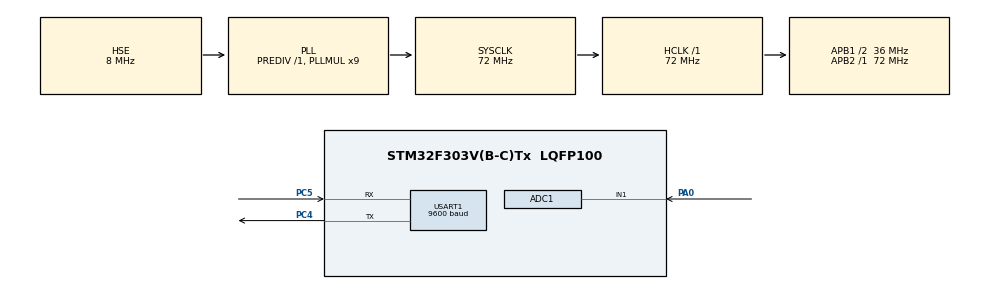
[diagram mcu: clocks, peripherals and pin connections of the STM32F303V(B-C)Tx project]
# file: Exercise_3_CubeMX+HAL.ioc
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ADC1.Channel-0\#ChannelRegularConversion=ADC_CHANNEL_1
ADC1.ContinuousConvMode=ENABLE
ADC1.NbrOfConversion=1
ADC1.NbrOfConversionFlag=1
ADC1.Offset-0\#ChannelRegularConversion=0
ADC1.OffsetNumber-0\#ChannelRegularConversion=ADC_OFFSET_NONE
ADC1.Rank-0\#ChannelRegularConversion=1
ADC1.Resolution=ADC_RESOLUTION_12B
ADC1.SamplingTime-0\#ChannelRegularConversion=ADC_SAMPLETIME_1CYCLE_5
ADC1.master=1
Dma.ADC1.0.Direction=DMA_PERIPH_TO_MEMORY
Dma.ADC1.0.Instance=DMA1_Channel1
Dma.ADC1.0.MemDataAlignment=DMA_MDATAALIGN_WORD
Dma.ADC1.0.MemInc=DMA_MINC_ENABLE
Dma.ADC1.0.Mode=DMA_NORMAL
Dma.ADC1.0.PeriphDataAlignment=DMA_PDATAALIGN_HALFWORD
Dma.ADC1.0.PeriphInc=DMA_PINC_DISABLE
Dma.ADC1.0.Priority=DMA_PRIORITY_LOW
Dma.Request0=ADC1
Dma.Request1=USART1_TX
Dma.USART1_TX.1.Direction=DMA_MEMORY_TO_PERIPH
Dma.USART1_TX.1.Instance=DMA1_Channel4
Dma.USART1_TX.1.MemDataAlignment=DMA_MDATAALIGN_BYTE
Dma.USART1_TX.1.MemInc=DMA_MINC_ENABLE
Dma.USART1_TX.1.Mode=DMA_NORMAL
Dma.USART1_TX.1.PeriphDataAlignment=DMA_PDATAALIGN_BYTE
Dma.USART1_TX.1.PeriphInc=DMA_PINC_DISABLE
Dma.USART1_TX.1.Priority=DMA_PRIORITY_LOW
Mcu.Family=STM32F3
Mcu.Name=STM32F303V(B-C)Tx
Mcu.Package=LQFP100
NVIC.DMA1_Channel1_IRQn=true\:0\:0\:false\:false\:true\:false\:true
NVIC.DMA1_Channel4_IRQn=true\:0\:0\:false\:false\:true\:false\:true
NVIC.PriorityGroup=NVIC_PRIORITYGROUP_4
PA0.Mode=IN1-Single-Ended
PA0.Signal=ADC1_IN1
PA13.Mode=Serial_Wire
PA13.Signal=SYS_JTMS-SWDIO
PA14.Mode=Serial_Wire
PA14.Signal=SYS_JTCK-SWCLK
PC4.Mode=Asynchronous
PC4.Signal=USART1_TX
PC5.Mode=Asynchronous
PC5.Signal=USART1_RX
PF0-OSC_IN.Mode=HSE-External-Clock-Source
PF0-OSC_IN.Signal=RCC_OSC_IN
ProjectManager.HeapSize=0x200
ProjectManager.StackSize=0x400
ProjectManager.TargetToolchain=MDK-ARM V5
RCC.ADC12PRES=RCC_ADC12PLLCLK_DIV2
RCC.AHBFreq_Value=72000000
RCC.APB1CLKDivider=RCC_HCLK_DIV2
RCC.APB1Freq_Value=36000000
RCC.APB1TimFreq_Value=72000000
RCC.APB2Freq_Value=72000000
RCC.APB2TimFreq_Value=72000000
RCC.CortexFreq_Value=72000000
RCC.HCLKFreq_Value=72000000
RCC.HSE_VALUE=8000000
RCC.HSI_VALUE=8000000
RCC.LSE_VALUE=32768
RCC.PLLMUL=RCC_PLL_MUL9
RCC.PLLSourceVirtual=RCC_PLLSOURCE_HSE
RCC.SYSCLKFreq_VALUE=72000000
RCC.SYSCLKSourceVirtual=RCC_SYSCLKSOURCE_PLLCLK
RCC.USBFreq_Value=72000000
USART1.BaudRate=9600
USART1.VirtualMode-Asynchronous=VM_ASYNC
board=custom

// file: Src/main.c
/* USER CODE BEGIN Header */
/**
  ******************************************************************************
  * @file           : main.c
  * @brief          : Main program body
  ******************************************************************************
  * @attention
  *
  * <h2><center>&copy; Copyright (c) 2019 STMicroelectronics.
  * All rights reserved.</center></h2>
  *
  * This software component is licensed by ST under BSD 3-Clause license,
  * the "License"; You may not use this file except in compliance with the
  * License. You may obtain a copy of the License at:
  *                        opensource.org/licenses/BSD-3-Clause
  *
  ******************************************************************************
  */
/* USER CODE END Header */

#include "main.h"
#include "adc.h"
#include "dma.h"
#include "usart.h"
#include "gpio.h"

/* USER CODE BEGIN Includes */
	#include <string.h>
	#include <stdio.h>

	#include <../Lib/arr.h>
/* USER CODE END Includes */

/* USER CODE BEGIN PD */

	#define ADC_SAMPLES 5

/* USER CODE END PD */

/* USER CODE BEGIN PV */

	/// store current ADC 8-bit values
	uint32_t adc_curr[ADC_SAMPLES];
	uint32_t adc_prev[ADC_SAMPLES];

	/// store ADC conversion compleate flag
	uint8_t adc_cplt_f = 0;

/* USER CODE END PV */

void SystemClock_Config(void);
/* USER CODE BEGIN PFP */

/** \brief	Set conversion compleat flag (redefined callback).
 *
 * \param[in] hadc	Pointer to ADC control struct.
 */
void HAL_ADC_ConvCpltCallback(ADC_HandleTypeDef* hadc)
{
	adc_cplt_f = 1;		// set conversion completed flag
}

/* USER CODE END PFP */

int main(void)
{

  /* MCU Configuration--------------------------------------------------------*/

  /* Reset of all peripherals, Initializes the Flash interface and the Systick. */
  HAL_Init();

  /* Configure the system clock */
  SystemClock_Config();

  /* Initialize all configured peripherals */
  MX_GPIO_Init();
  MX_DMA_Init();
  MX_ADC1_Init();
  MX_USART1_UART_Init();
  /* USER CODE BEGIN 2 */

	uint8_t welcome_msg[] = {"\n\r12bit ADC1 ch1 - PA0 (Blue button) values:\n\r"};
	HAL_UART_Transmit(&huart1, welcome_msg, strlen((char*)welcome_msg), 1000);

  /* USER CODE END 2 */

  /* Infinite loop */
  /* USER CODE BEGIN WHILE */

	HAL_ADC_Start_DMA(&hadc1, adc_curr, ADC_SAMPLES);

  while (1)
  {
	if (adc_cplt_f == 1) {
		// test for changing ADC measurements relative to adc_prev[]
		int8_t res = -1;
		res = arr_cmp(adc_prev, adc_curr, ADC_SAMPLES);

		if ( res >= 0) {
			// display measured(changed) values
			arr_print(adc_curr, ADC_SAMPLES);

			// 'shift' current -> previous
			arr_cpy(adc_prev, adc_curr, ADC_SAMPLES);
		}
		adc_cplt_f = 0;		// clear conversion compleated flag

		HAL_ADC_Start_DMA(&hadc1, adc_curr, ADC_SAMPLES);

		HAL_Delay(50);		// user friendly speed down
	}

    /* USER CODE END WHILE */

  }
}

void SystemClock_Config(void)
{
  RCC_OscInitTypeDef RCC_OscInitStruct = {0};
  RCC_ClkInitTypeDef RCC_ClkInitStruct = {0};
  RCC_PeriphCLKInitTypeDef PeriphClkInit = {0};

  /** Initializes the CPU, AHB and APB busses clocks
  */
  RCC_OscInitStruct.OscillatorType = RCC_OSCILLATORTYPE_HSE;
  RCC_OscInitStruct.HSEState = RCC_HSE_BYPASS;
  RCC_OscInitStruct.HSEPredivValue = RCC_HSE_PREDIV_DIV1;
  RCC_OscInitStruct.HSIState = RCC_HSI_ON;
  RCC_OscInitStruct.PLL.PLLState = RCC_PLL_ON;
  RCC_OscInitStruct.PLL.PLLSource = RCC_PLLSOURCE_HSE;
  RCC_OscInitStruct.PLL.PLLMUL = RCC_PLL_MUL9;
  if (HAL_RCC_OscConfig(&RCC_OscInitStruct) != HAL_OK)
  {
    Error_Handler();
  }
  /** Initializes the CPU, AHB and APB busses clocks
  */
  RCC_ClkInitStruct.ClockType = RCC_CLOCKTYPE_HCLK|RCC_CLOCKTYPE_SYSCLK
                              |RCC_CLOCKTYPE_PCLK1|RCC_CLOCKTYPE_PCLK2;
  RCC_ClkInitStruct.SYSCLKSource = RCC_SYSCLKSOURCE_PLLCLK;
  RCC_ClkInitStruct.AHBCLKDivider = RCC_SYSCLK_DIV1;
  RCC_ClkInitStruct.APB1CLKDivider = RCC_HCLK_DIV2;
  RCC_ClkInitStruct.APB2CLKDivider = RCC_HCLK_DIV1;

  if (HAL_RCC_ClockConfig(&RCC_ClkInitStruct, FLASH_LATENCY_2) != HAL_OK)
  {
    Error_Handler();
  }
  PeriphClkInit.PeriphClockSelection = RCC_PERIPHCLK_USART1|RCC_PERIPHCLK_ADC12;
  PeriphClkInit.Usart1ClockSelection = RCC_USART1CLKSOURCE_PCLK2;
  PeriphClkInit.Adc12ClockSelection = RCC_ADC12PLLCLK_DIV2;
  if (HAL_RCCEx_PeriphCLKConfig(&PeriphClkInit) != HAL_OK)
  {
    Error_Handler();
  }
}

void Error_Handler(void)
{
}

/************************ (C) COPYRIGHT STMicroelectronics *****END OF FILE****/
